# M460 register map
File version: 1.0
Registers are 32-bit, read-write, reset 0x0 unless marked. A register's access mark holds for its fields unless they carry their own. Offsets are from the block's base; [hi:lo] are bit positions; {n}, {i} and the like mark numbered series; 'fields as' and 'values as' point back to an identical list.

## PDMA0 — PDMA Register Map
Base 0x40008000
Same registers: PDMA1 0x40018000
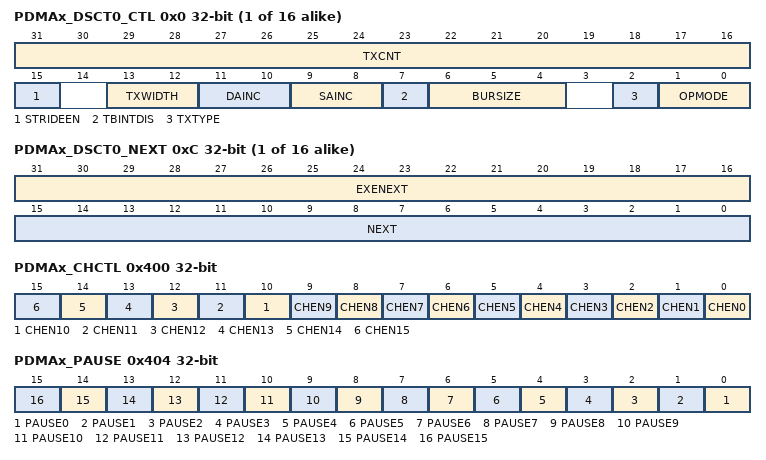
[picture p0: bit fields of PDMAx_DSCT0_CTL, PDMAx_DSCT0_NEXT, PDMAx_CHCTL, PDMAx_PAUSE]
{0x0+0x10*i} PDMAx_DSCT{i}_CTL reset not defined (i=0..15) — Descriptor Table Control Register of PDMA Channel n
  [31:16] TXCNT — Transfer Count. The TXCNT represents the required number of PDMA transfer, the real transfer count is (TXCNT + 1); The maximum transfer count is 65536, every transfer may be byte, half-word or word that is dependent on TXWIDTH field. Note: When PDMA finishes each transfer data, this field will be decreased immediately.
  [15] STRIDEEN — Stride Mode Enable Bit
    0=Stride transfer mode Disabled; 1=Stride transfer mode Enabled
  [13:12] TXWIDTH — Transfer Width Selection. This field is used for transfer width. Note: The PDMA transfer source address (PDMA_DSCTn_SA) and PDMA transfer destination address (PDMA_DSCTn_DA) should be alignment under the TXWIDTH selection
    0=One byte (8 bit) is transferred for every operation; 1=One half-word (16 bit) is transferred for every operation; 2=One word (32-bit) is transferred for every operation
  [11:10] DAINC — Destination Address Increment. This field is used to set the destination address increment size. Note: The fixed address function does not support in memory to memory transfer type.
    3=No increment (fixed address)
  [9:8] SAINC — Source Address Increment. This field is used to set the source address increment size. Note: The fixed address function does not support in memory to memory transfer type.
    3=No increment (fixed address)
  [7] TBINTDIS — Table Interrupt Disable Bit. This field can be used to decide whether to enable table interrupt or not. If the TBINTDIS bit is enabled it will not generates TDIFn(PDMA_TDSTS[7:0]) when PDMA controller finishes transfer task. Note: This function only for Scatter-gather mode.
    0=Table interrupt Enabled; 1=Table interrupt Disabled
  [6:4] BURSIZE — Burst Size. This field is used for peripheral to determine the burst size or used for determine the re-arbitration size. Note: This field is only useful in burst transfer type.
    0=128 Transfers; 1=64 Transfers; 2=32 Transfers; 3=16 Transfers; 4=8 Transfers; 5=4 Transfers; 6=2 Transfers; 7=1 Transfers
  [2] TXTYPE — Transfer Type
    0=Burst transfer type; 1=Single transfer type
  [1:0] OPMODE — PDMA Operation Mode Selection. Note: Before filling new transfer task in the Descriptor Table, user must check the PDMA_INTSTS[1] to make sure the current task is complete.
    0=Idle state: Channel is stopped or this table is complete, when PDMA finish channel table task, OPMODE will be cleared to idle state automatically; 1=Basic mode: The descriptor table only has one task. When this task is finished, the PDMA_INTSTS[1] will be asserted; 2=Scatter-gather mode: When operating in this mode, user must give the next descriptor table address in PDMA_DSCTn_NEXT register; PDMA controller will ignore this task, then load the next task to execute
{0x4+0x10*i} PDMAx_DSCT{i}_SA reset not defined (i=0..15) — Source Address Register of PDMA Channel n
  [31:0] SA — PDMA Transfer Source Address. This field indicates a 32-bit source address of PDMA controller.
{0x8+0x10*i} PDMAx_DSCT{i}_DA reset not defined (i=0..15) — Destination Address Register of PDMA Channel n
  [31:0] DA — PDMA Transfer Destination Address. This field indicates a 32-bit destination address of PDMA controller.
{0xC+0x10*i} PDMAx_DSCT{i}_NEXT reset not defined (i=0..15) — Next Scatter-gather Descriptor Table Offset Address of PDMA Channel n
  [31:16] EXENEXT — PDMA Execution Next Descriptor Table Offset. This field indicates the offset of next descriptor table address of current execution descriptor table in system memory. Note: Write operation is useless in this field.
  [15:0] NEXT — PDMA Next Descriptor Table Offset. This field indicates the offset of the next descriptor table address in system memory. Write Operation: If the system memory based address is 0x2000_0000 (PDMA_SCATBA), and the next descriptor table is start from 0x2000_0100, then this field must fill in 0x0100. Read Operation: When operating in Scatter-gather mode, the last two bits NEXT[1:0] will become reserved, and indicate the first next address of system memory. Note 1: The descriptor table address must be word boundary. Note 2: Before filling transfer task in the descriptor table, user must check if the descriptor table is complete.
{0x80+4i} PDMAx_CURSCAT{i} ro reset not defined (i=0..15) — Current Scatter-gather Descriptor Table Address of PDMA Channel n
  [31:0] CURADDR — PDMA Current Description Address (Read Only). This field indicates a 32-bit current external description address of PDMA controller. Note: This field is read only and used for Scatter-gather mode only to indicate the current external description address.
0x400 PDMAx_CHCTL — PDMA Channel Control Register
  [all] fields
    0=PDMA channel [n] Disabled; 1=PDMA channel [n] Enabled
  [n] CHEN{n} (n=0..15) — PDMA Channel Enable Bits. Set this bit to 1 to enable PDMAn operation. Channel cannot be active if it is not set as enabled. Note: Setting the corresponding bit of PDMA_PAUSE or PDMA_CHRST register will also clear this bit.
0x404 PDMAx_PAUSE wo — PDMA Transfer Pause Control Register
  [all] fields
    0=No effect; 1=Pause PDMA channel n transfer
  [n] PAUSE{n} (n=0..15) — PDMA Channel n Transfer Pause Control (Write Only)
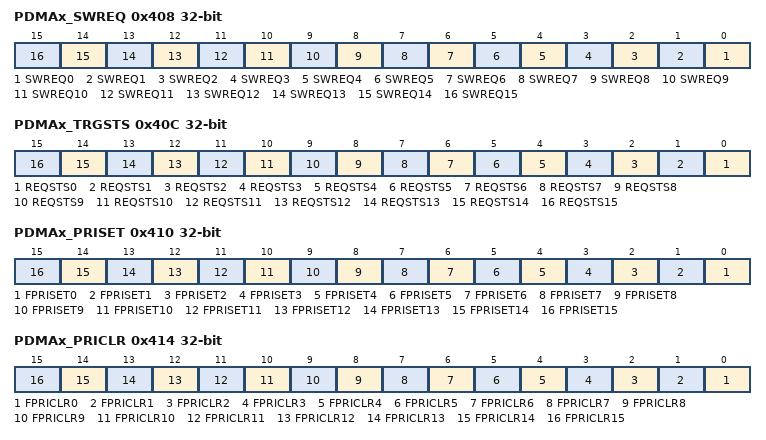
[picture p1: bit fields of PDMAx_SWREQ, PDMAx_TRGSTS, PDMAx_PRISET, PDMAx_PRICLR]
0x408 PDMAx_SWREQ wo — PDMA Software Request Register
  [all] fields
    0=No effect; 1=Generate a software request
  [n] SWREQ{n} (n=0..15) — PDMA Software Request (Write Only). Set this bit to 1 to generate a software request to PDMA [n]. Note 1: User can read PDMA_TRGSTS register to know which channel is on active. Active flag may be triggered by software request or peripheral request. Note 2: If user does not enable corresponding PDMA channel, the software request will be ignored.
0x40C PDMAx_TRGSTS ro — PDMA Channel Request Status Register
  [all] fields
    0=PDMA Channel n has no request; 1=PDMA Channel n has a request
  [n] REQSTS{n} (n=0..15) — PDMA Channel Request Status (Read Only). This flag indicates whether channel[n] have a request or not, no matter request from software or peripheral. When PDMA controller finishes channel transfer, this bit will be cleared automatically. Note: If user pauses or resets each PDMA transfer by setting PDMA_PAUSE or PDMA_CHRST register respectively, this bit will be cleared automatically after finishing the current transfer.
0x410 PDMAx_PRISET — PDMA Fixed Priority Setting Register
  [all] fields
    0=No effect. Corresponding PDMA channel is round-robin priority; 1=Set PDMA channel [n] to fixed priority channel. Corresponding PDMA channel is fixed priority
  [n] FPRISET{n} (n=0..15) — PDMA Fixed Priority Setting. Set this bit to 1 to enable fixed priority level. Write Operation: Note: This field is only set to fixed priority. To clear fixed priority, use PDMA_PRICLR register.
0x414 PDMAx_PRICLR wo — PDMA Fixed Priority Clear Register
  [all] fields
    0=No effect; 1=Clear PDMA channel [n] fixed priority setting
  [n] FPRICLR{n} (n=0..15) — PDMA Fixed Priority Clear Bits (Write Only). Set this bit to 1 to clear fixed priority level. Note: User can read PDMA_PRISET register to know the channel priority.
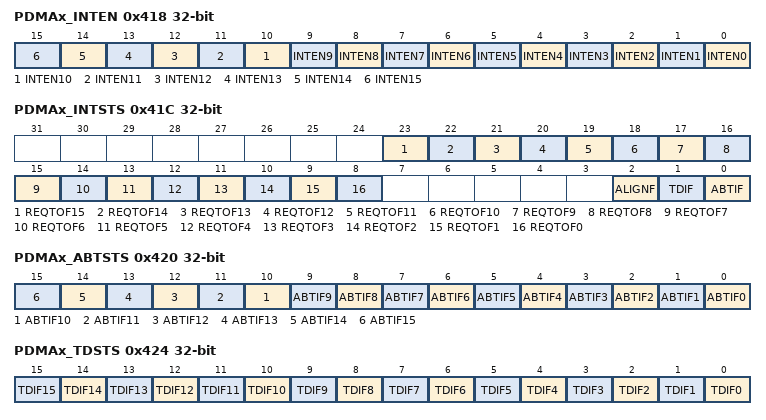
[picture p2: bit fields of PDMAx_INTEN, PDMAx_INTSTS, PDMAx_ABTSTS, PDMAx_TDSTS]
0x418 PDMAx_INTEN — PDMA Interrupt Enable Register
  [all] fields
    0=PDMA channel n interrupt Disabled; 1=PDMA channel n interrupt Enabled
  [n] INTEN{n} (n=0..15) — PDMA Interrupt Enable Bits. This field is used to enable PDMA channel[n] interrupt. Note: The interrupt flag is time-out, abort, transfer done and align.
0x41C PDMAx_INTSTS — PDMA Interrupt Status Register
  [23] REQTOF15 — Request Time-out Flag for Channel 15. This flag indicates that PDMA controller has waited peripheral request for a period defined by TOC15(PDMA_TOC15_14[31:16]). Note 1: Please disable time-out function before clearing this bit. Note 2: This bit will be cleared by writing 1 to it.
    0=No request time-out; 1=Peripheral request time-out
  [22] REQTOF14 — Request Time-out Flag for Channel 14. This flag indicates that PDMA controller has waited peripheral request for a period defined by TOC14(PDMA_TOC15_14[15:0]). Note 1: Please disable time-out function before clearing this bit. Note 2: This bit will be cleared by writing 1 to it.
    0=No request time-out; 1=Peripheral request time-out
  [21] REQTOF13 — Request Time-out Flag for Channel 13. This flag indicates that PDMA controller has waited peripheral request for a period defined by TOC13(PDMA_TOC13_12[31:16]). Note 1: Please disable time-out function before clearing this bit. Note 2: This bit will be cleared by writing 1 to it.
    0=No request time-out; 1=Peripheral request time-out
  [20] REQTOF12 — Request Time-out Flag for Channel 12. This flag indicates that PDMA controller has waited peripheral request for a period defined by TOC12(PDMA_TOC13_12[15:0]). Note 1: Please disable time-out function before clearing this bit. Note 2: This bit will be cleared by writing 1 to it.
    0=No request time-out; 1=Peripheral request time-out
  [19] REQTOF11 — Request Time-out Flag for Channel 11. This flag indicates that PDMA controller has waited peripheral request for a period defined by TOC11(PDMA_TOC10_11[31:16]). Note 1: Please disable time-out function before clearing this bit. Note 2: This bit will be cleared by writing 1 to it.
    0=No request time-out; 1=Peripheral request time-out
  [18] REQTOF10 — Request Time-out Flag for Channel 10. This flag indicates that PDMA controller has waited peripheral request for a period defined by TOC10(PDMA_TOC10_11[15:0]). Note 1: Please disable time-out function before clearing this bit. Note 2: This bit will be cleared by writing 1 to it.
    0=No request time-out; 1=Peripheral request time-out
  [17] REQTOF9 — Request Time-out Flag for Channel 9. This flag indicates that PDMA controller has waited peripheral request for a period defined by TOC9(PDMA_TOC8_9[31:16]). Note 1: Please disable time-out function before clearing this bit. Note 2: This bit will be cleared by writing 1 to it.
    0=No request time-out; 1=Peripheral request time-out
  [16] REQTOF8 — Request Time-out Flag for Channel 8. This flag indicates that PDMA controller has waited peripheral request for a period defined by TOC8(PDMA_TOC8_9[15:0]). Note 1: Please disable time-out function before clearing this bit. Note 2: This bit will be cleared by writing 1 to it.
    0=No request time-out; 1=Peripheral request time-out
  [15] REQTOF7 — Request Time-out Flag for Channel 7. This flag indicates that PDMA controller has waited peripheral request for a period defined by TOC7(PDMA_TOC6_7[31:16]). Note 1: Please disable time-out function before clearing this bit. Note 2: This bit will be cleared by writing 1 to it.
    0=No request time-out; 1=Peripheral request time-out
  [14] REQTOF6 — Request Time-out Flag for Channel 6. This flag indicates that PDMA controller has waited peripheral request for a period defined by TOC6(PDMA_TOC6_7[15:0]). Note 1: Please disable time-out function before clearing this bit. Note 2: This bit will be cleared by writing 1 to it.
    0=No request time-out; 1=Peripheral request time-out
  [13] REQTOF5 — Request Time-out Flag for Channel 5. This flag indicates that PDMA controller has waited peripheral request for a period defined by TOC5(PDMA_TOC4_5[31:16]). Note 1: Please disable time-out function before clearing this bit. Note 2: This bit will be cleared by writing 1 to it.
    0=No request time-out; 1=Peripheral request time-out
  [12] REQTOF4 — Request Time-out Flag for Channel 4. This flag indicates that PDMA controller has waited peripheral request for a period defined by TOC4(PDMA_TOC4_5[15:0]). Note 1: Please disable time-out function before clearing this bit. Note 2: This bit will be cleared by writing 1 to it.
    0=No request time-out; 1=Peripheral request time-out
  [11] REQTOF3 — Request Time-out Flag for Channel 3. This flag indicates that PDMA controller has waited peripheral request for a period defined by TOC3(PDMA_TOC2_3[31:16]). Note 1: Please disable time-out function before clearing this bit. Note 2: This bit will be cleared by writing 1 to it.
    0=No request time-out; 1=Peripheral request time-out
  [10] REQTOF2 — Request Time-out Flag for Channel 2. This flag indicates that PDMA controller has waited peripheral request for a period defined by TOC2(PDMA_TOC2_3[15:0]). Note 1: Please disable time-out function before clearing this bit. Note 2: This bit will be cleared by writing 1 to it.
    0=No request time-out; 1=Peripheral request time-out
  [9] REQTOF1 — Request Time-out Flag for Channel 1. This flag indicates that PDMA controller has waited peripheral request for a period defined by TOC1(PDMA_TOC0_1[31:16]). Note 1: Please disable time-out function before clearing this bit. Note 2: This bit will be cleared by writing 1 to it.
    0=No request time-out; 1=Peripheral request time-out
  [8] REQTOF0 — Request Time-out Flag for Channel 0. This flag indicates that PDMA controller has waited peripheral request for a period defined by TOC0(PDMA_TOC0_1[15:0]. Note 1: Please disable time-out function before clearing this bit. Note 2: This bit will be cleared by writing 1 to it.
    0=No request time-out; 1=Peripheral request time-out
  [2] ALIGNF ro — Transfer Alignment Interrupt Flag (Read Only)
    0=PDMA channel source address and destination address both follow transfer width setting; 1=PDMA channel source address or destination address is not follow transfer width setting
  [1] TDIF ro — Transfer Done Interrupt Flag (Read Only). This bit indicates that PDMA controller has finished transmission; User can read PDMA_TDSTS register to indicate which channel finished transfer.
    0=Not finished yet; 1=PDMA channel has finished transmission
  [0] ABTIF ro — PDMA Read/Write Target Abort Interrupt Flag (Read Only). This bit indicates that PDMA has target abort error; Software can read PDMA_ABTSTS register to find which channel has target abort error.
    0=No AHB bus ERROR response received; 1=AHB bus ERROR response received
0x420 PDMAx_ABTSTS — PDMA Channel Read/Write Target Abort Flag Register
  [all] fields
    0=No AHB bus ERROR response received when channel n transfer; 1=AHB bus ERROR response received when channel n transfer
  [n] ABTIF{n} (n=0..15) — PDMA Read/Write Target Abort Interrupt Status Flag. This bit indicates which PDMA controller has target abort error. Note 1: If channel n target abort, REQSRCn should set0 to disable peripheral request. Note 2 This bit will be cleared by writing 1 to it.
0x424 PDMAx_TDSTS — PDMA Channel Transfer Done Flag Register
  [all] fields
    0=PDMA channel transfer has not finished; 1=PDMA channel has finished transmission
  [n] TDIF{n} (n=0..15) — Transfer Done Flag. This bit indicates whether PDMA controller channel transfer has been finished or not. Note: User can write 1 to clear these bits.
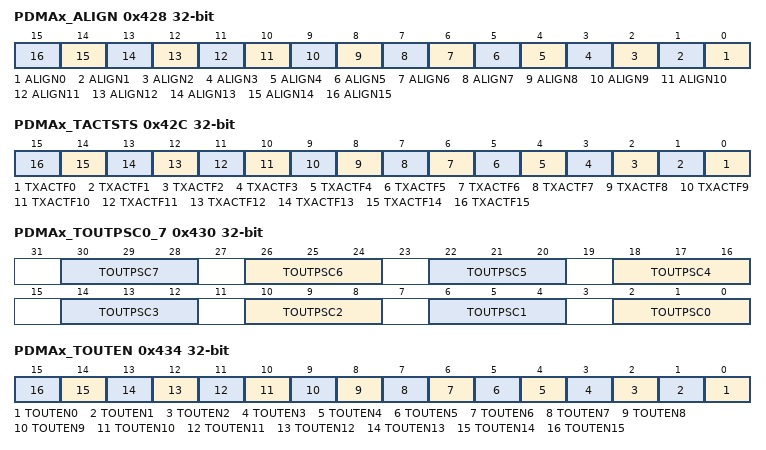
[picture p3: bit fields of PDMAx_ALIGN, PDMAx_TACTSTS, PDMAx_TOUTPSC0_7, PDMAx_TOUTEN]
0x428 PDMAx_ALIGN — PDMA Transfer Alignment Status Register
  [all] fields
    values as PDMAx_INTSTS.ALIGNF
  [n] ALIGN{n} (n=0..15) — Transfer Alignment Flag. This bit indicates whether source and destination address both follow transfer width setting. Note: User can write 1 to clear these bits.
0x42C PDMAx_TACTSTS ro — PDMA Transfer Active Flag Register
  [all] fields
    0=PDMA channel is finished; 1=PDMA channel is active
  [n] TXACTF{n} (n=0..15) — Transfer on Active Flag (Read Only). This bit indicates which PDMA channel is in active.
0x430 PDMAx_TOUTPSC0_7 — PDMA Time-out Prescaler Register(CH0 to CH7)
  [4n+2:4n] TOUTPSC{n} (n=0..7) — PDMA Channel {n} Time-out Clock Source Prescaler Bits
    0=PDMA channel {n} time-out clock source is HCLK/28; 1=PDMA channel {n} time-out clock source is HCLK/29; {v}=PDMA channel {n} time-out clock source is HCLK/{v+208} (v=2..7)
0x434 PDMAx_TOUTEN — PDMA Time-out Enable Register
  [all] fields
    0=PDMA Channel n time-out function Disabled; 1=PDMA Channel n time-out function Enabled
  [n] TOUTEN{n} (n=0..15) — PDMA Time-out Enable Bits
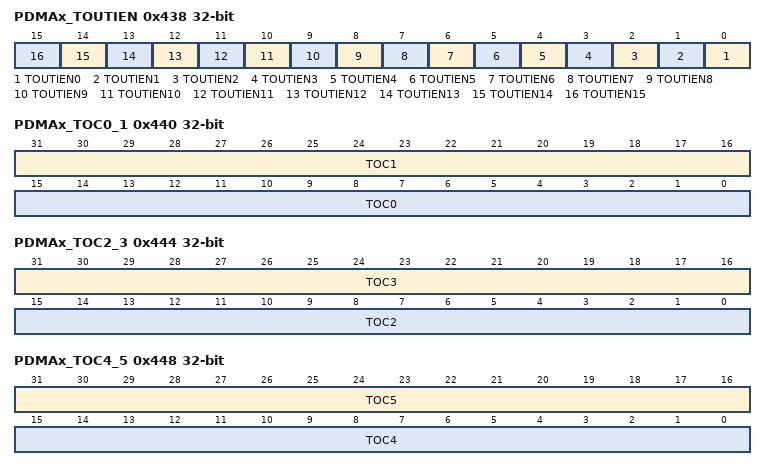
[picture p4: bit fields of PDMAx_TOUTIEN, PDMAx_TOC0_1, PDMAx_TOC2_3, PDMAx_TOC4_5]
0x438 PDMAx_TOUTIEN — PDMA Time-out Interrupt Enable Register
  [all] fields
    0=PDMA Channel n time-out interrupt Disabled; 1=PDMA Channel n time-out interrupt Enabled
  [n] TOUTIEN{n} (n=0..15) — PDMA Time-out Interrupt Enable Bits
0x43C PDMAx_SCATBA reset 0x20000000 — PDMA Scatter-gather Descriptor Table Base Address Register
  [31:16] SCATBA — PDMA Scatter-gather Descriptor Table Address. In Scatter-gather mode, this is the base address for calculating the next link - list address. The next link address equation is. Note: Only useful in Scatter-gather mode.
0x440 PDMAx_TOC0_1 — PDMA Time-out Counter Ch0 and Ch1 Register
  [31:16] TOC1 — Time-out Counter for Channel 1. This controls the period of time-out function for channel 1. The calculation unit is based on TOUTPSC1 (PDMA_TOUTPSC0_7[6:4]) clock. The example of time-out period can refer TOC0 bit description.
  [15:0] TOC0 — Time-out Counter for Channel 0. This controls the period of time-out function for channel 0. The calculation unit is based on TOUTPSC0 (PDMA_TOUTPSC0_7[2:0]) clock.
0x444 PDMAx_TOC2_3 — PDMA Time-out Counter Ch2 and Ch3 Register
  [31:16] TOC3 — Time-out Counter for Channel 3. This controls the period of time-out function for channel 3. The calculation unit is based on TOUTPSC3 (PDMA_TOUTPSC0_7[14:12]) clock. The example of time-out period can refer TOC0 bit description.
  [15:0] TOC2 — Time-out Counter for Channel 2. This controls the period of time-out function for channel 2. The calculation unit is based on TOUTPSC2 (PDMA_TOUTPSC0_7[10:8]) clock.
0x448 PDMAx_TOC4_5 — PDMA Time-out Counter Ch4 and Ch5 Register
  [31:16] TOC5 — Time-out Counter for Channel 5. This controls the period of time-out function for channel 5. The calculation unit is based on TOUTPSC5 (PDMA_TOUTPSC0_7[22:20]) clock. The example of time-out period can refer TOC0 bit description.
  [15:0] TOC4 — Time-out Counter for Channel 4. This controls the period of time-out function for channel 4. The calculation unit is based on TOUTPSC4 (PDMA_TOUTPSC0_7[18:16]) clock.
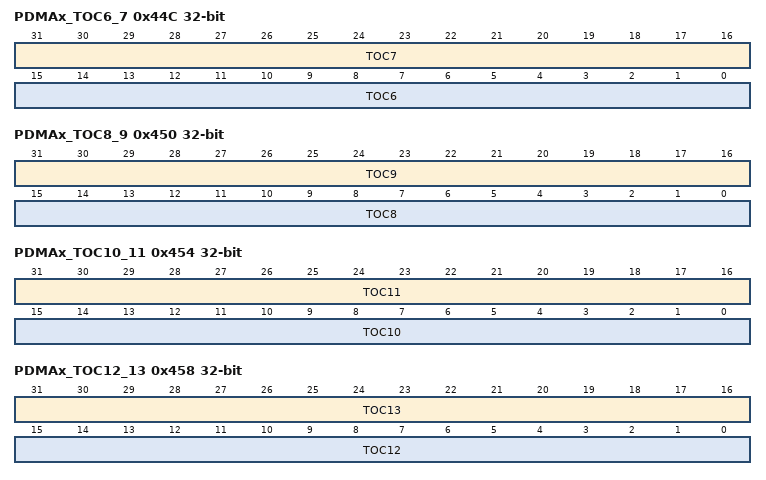
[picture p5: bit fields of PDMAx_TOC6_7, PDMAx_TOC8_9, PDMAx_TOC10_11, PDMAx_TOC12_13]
0x44C PDMAx_TOC6_7 — PDMA Time-out Counter Ch6 and Ch7 Register
  [31:16] TOC7 — Time-out Counter for Channel 7. This controls the period of time-out function for channel 7. The calculation unit is based on TOUTPSC7 (PDMA_TOUTPSC0_7[30:28]) clock. The example of time-out period can refer TOC0 bit description.
  [15:0] TOC6 — Time-out Counter for Channel 6. This controls the period of time-out function for channel 6. The calculation unit is based on TOUTPSC6 (PDMA_TOUTPSC0_7[26:24]) clock.
0x450 PDMAx_TOC8_9 — PDMA Time-out Counter Ch8 and Ch9 Register
  [31:16] TOC9 — Time-out Counter for Channel 9. This controls the period of time-out function for channel 9. The calculation unit is based on TOUTPSC9 (PDMA_TOUTPSC8_15[6:4]) clock. The example of time-out period can refer TOC0 bit description.
  [15:0] TOC8 — Time-out Counter for Channel 8. This controls the period of time-out function for channel 8. The calculation unit is based on TOUTPSC8 (PDMA_TOUTPSC8_15[2:0]) clock.
0x454 PDMAx_TOC10_11 — PDMA Time-out Counter Ch10 and Ch11 Register
  [31:16] TOC11 — Time-out Counter for Channel 11. This controls the period of time-out function for channel 11. The calculation unit is based on TOUTPSC11 (PDMA_TOUTPSC8_15[14:12]) clock. The example of time-out period can refer TOC0 bit description.
  [15:0] TOC10 — Time-out Counter for Channel 10. This controls the period of time-out function for channel 10. The calculation unit is based on TOUTPSC10 (PDMA_TOUTPSC8_15[10:8]) clock.
0x458 PDMAx_TOC12_13 — PDMA Time-out Counter Ch12 and Ch13 Register
  [31:16] TOC13 — Time-out Counter for Channel 13. This controls the period of time-out function for channel 13. The calculation unit is based on TOUTPSC13 (PDMA_TOUTPSC8_15[22:20]) clock. The example of time-out period can refer TOC0 bit description.
  [15:0] TOC12 — Time-out Counter for Channel 12. This controls the period of time-out function for channel 12. The calculation unit is based on TOUTPSC12 (PDMA_TOUTPSC8_15[18:16]) clock.
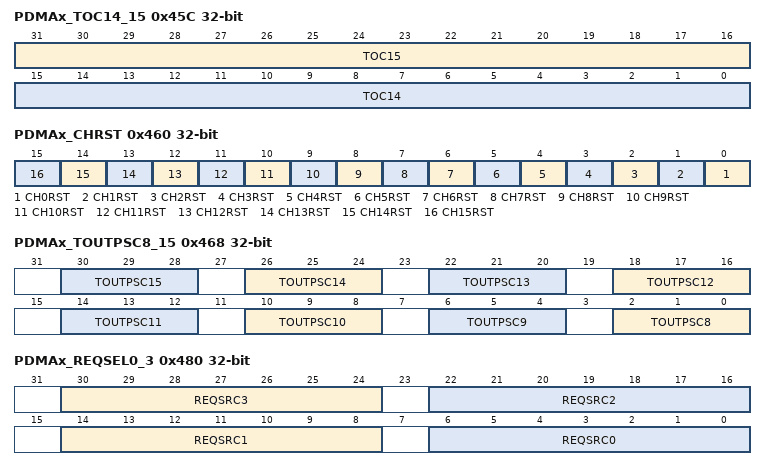
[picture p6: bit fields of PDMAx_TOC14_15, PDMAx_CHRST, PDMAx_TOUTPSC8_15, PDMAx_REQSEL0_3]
0x45C PDMAx_TOC14_15 — PDMA Time-out Counter Ch14 and Ch15 Register
  [31:16] TOC15 — Time-out Counter for Channel 15. This controls the period of time-out function for channel 15. The calculation unit is based on TOUTPSC15 (PDMA_TOUTPSC8_15[30:28]) clock. The example of time-out period can refer TOC0 bit description.
  [15:0] TOC14 — Time-out Counter for Channel 14. This controls the period of time-out function for channel 14. The calculation unit is based on TOUTPSC14 (PDMA_TOUTPSC8_15[26:24]) clock.
0x460 PDMAx_CHRST — PDMA Channel Reset Register
  [all] fields
    0=Corresponding channel n is not reset; 1=Corresponding channel n is reset
  [n] CH{n}RST (n=0..15) — Channel n Reset
0x468 PDMAx_TOUTPSC8_15 — PDMA Time-out Prescaler Register(CH8 to CH15)
  [4n-30:4n-32] TOUTPSC{n} (n=8..15) — PDMA Channel {n} Time-out Clock Source Prescaler Bits
    values as PDMAx_TOUTPSC0_7.TOUTPSC0
0x480 PDMAx_REQSEL0_3 — PDMA Request Source Select Register 0
  [30:24] REQSRC3 — Channel 3 Request Source Selection. This filed defines which peripheral is connected to PDMA channel 3. User can configure the peripheral setting by REQSRC3. Note: The channel configuration is the same as REQSRC0 field. Please refer to the explanation of REQSRC0.
  [22:16] REQSRC2 — Channel 2 Request Source Selection. This filed defines which peripheral is connected to PDMA channel 2. User can configure the peripheral setting by REQSRC2. Note: The channel configuration is the same as REQSRC0 field. Please refer to the explanation of REQSRC0.
  [14:8] REQSRC1 — Channel 1 Request Source Selection. This filed defines which peripheral is connected to PDMA channel 1. User can configure the peripheral setting by REQSRC1. Note: The channel configuration is the same as REQSRC0 field. Please refer to the explanation of REQSRC0.
  [6:0] REQSRC0 — Channel 0 Request Source Selection. This filed defines which peripheral is connected to PDMA channel 0. User can configure the peripheral by setting REQSRC0. Note 1: A peripheral cannot be assigned to two channels at the same time. Note 2: This field is useless when transfer between memory and memory.
    0=Disable PDMA peripheral request; 2=Channel connects to USB_TX; 3=Channel connects to USB_RX; 4=Channel connects to UART0_TX; 5=Channel connects to UART0_RX; 6=Channel connects to UART1_TX; 7=Channel connects to UART1_RX; 8=Channel connects to UART2_TX; 9=Channel connects to UART2_RX; 10=Channel connects to UART3_TX; 11=Channel connects to UART3_RX; 12=Channel connects to UART4_TX; 13=Channel connects to UART4_RX; 14=Channel connects to UART5_TX; 15=Channel connects to UART5_RX; 16=Channel connects to USCI0_TX; 17=Channel connects to USCI0_RX; 20=Channel connects to QSPI0_TX; 21=Channel connects to QSPI0_RX; 22=Channel connects to SPI0_TX; 23=Channel connects to SPI0_RX; 24=Channel connects to SPI1_TX; 25=Channel connects to SPI1_RX; 26=Channel connects to SPI2_TX; 27=Channel connects to SPI2_RX; 28=Channel connects to SPI3_TX; 29=Channel connects to SPI3_RX; 30=Channel connects to QSPI1_TX; 31=Channel connects to QSPI1_RX; 32=Channel connects to EPWM0_P1_RX; 33=Channel connects to EPWM0_P2_RX; 34=Channel connects to EPWM0_P3_RX; 35=Channel connects to EPWM1_P1_RX; 36=Channel connects to EPWM1_P2_RX; 37=Channel connects to EPWM1_P3_RX; 38=Channel connects to I2C0_TX; 39=Channel connects to I2C0_RX; 40=Channel connects to I2C1_TX; 41=Channel connects to I2C1_RX; 42=Channel connects to I2C2_TX; 43=Channel connects to I2C2_RX; 44=Channel connects to I2S0_TX; 45=Channel connects to I2S0_RX; {v}=Channel connects to TMR{v-46} (v=46..49); 50=Channel connects to ADC0_RX; 51=Channel connects to DAC0_TX; 52=Channel connects to DAC1_TX; {v}=Channel connects to EPWM0_CH{v-53}_TX (v=53..58); {v}=Channel connects to EPWM1_CH{v-59}_TX (v=59..64); 66=Channel connects to UART6_TX; 67=Channel connects to UART6_RX; 68=Channel connects to UART7_TX; 69=Channel connects to UART7_RX; 70=Channel connects to ADC1_RX; 71=Channel connects to ACMP0; 72=Channel connects to ACMP1; 73=Channel connects to PSIO_TX; 74=Channel connects to PSIO_RX; 75=Channel connects to I2C3_TX; 76=Channel connects to I2C3_RX; 77=Channel connects to I2C4_TX; 78=Channel connects to I2C4_RX; 79=Channel connects to I2S1_TX; 80=Channel connects to I2S1_RX; {v}=Channel connects to EINT{v-81} (v=81..88); 89=Channel connects to UART8_TX; 90=Channel connects to UART8_RX; 91=Channel connects to UART9_TX; 92=Channel connects to UART9_RX; 93=Channel connects to ADC2_RX; 94=Channel connects to ACMP2; 95=Channel connects to ACMP3; 96=Channel connects to SPI4_TX; 97=Channel connects to SPI4_RX; 98=Channel connects to SPI5_TX; 99=Channel connects to SPI5_RX; 100=Channel connects to SPI6_TX; 101=Channel connects to SPI6_RX; 102=Channel connects to SPI7_TX; 103=Channel connects to SPI7_RX; 104=Channel connects to SPI8_TX; 105=Channel connects to SPI8_RX; 106=Channel connects to SPI9_TX; 107=Channel connects to SPI9_RX; 108=Channel connects to SPI10_TX; 109=Channel connects to SPI10_RX
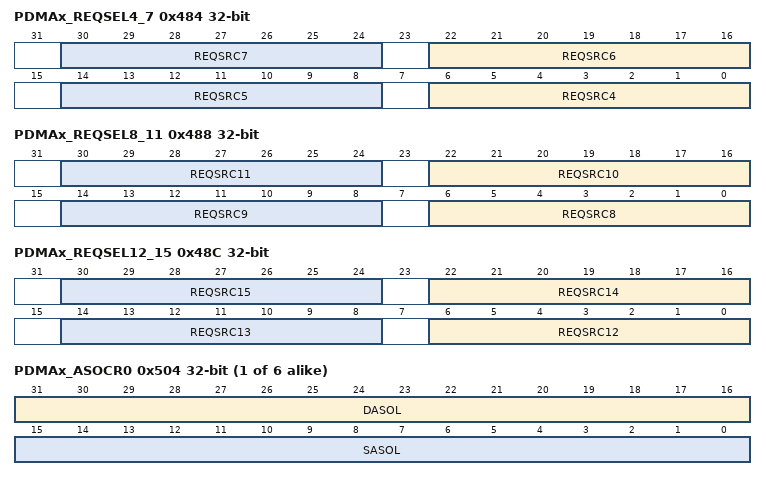
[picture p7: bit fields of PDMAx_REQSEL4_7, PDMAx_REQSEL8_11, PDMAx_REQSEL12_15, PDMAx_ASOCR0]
0x484 PDMAx_REQSEL4_7 — PDMA Request Source Select Register 1
  [8n-26:8n-32] REQSRC{n} (n=4..7) — Channel {n} Request Source Selection. This filed defines which peripheral is connected to PDMA channel {n}. User can configure the peripheral setting by REQSRC{n}. Note: The channel configuration is the same as REQSRC0 field. Please refer to the explanation of REQSRC0.
0x488 PDMAx_REQSEL8_11 — PDMA Request Source Select Register 2
  [8n-58:8n-64] REQSRC{n} (n=8..11) — Channel {n} Request Source Selection. This filed defines which peripheral is connected to PDMA channel {n}. User can configure the peripheral setting by REQSRC{n}. Note: The channel configuration is the same as REQSRC0 field. Please refer to the explanation of REQSRC0.
0x48C PDMAx_REQSEL12_15 — PDMA Request Source Select Register 3
  [8n-90:8n-96] REQSRC{n} (n=12..15) — Channel {n} Request Source Selection. This filed defines which peripheral is connected to PDMA channel {n}. User can configure the peripheral setting by REQSRC{n}. Note: The channel configuration is the same as REQSRC0 field. Please refer to the explanation of REQSRC0.
{0x500+8i} PDMAx_STCR{i} (i=0..5) — Stride Transfer Count Register of PDMA Channel {i}
  [15:0] STC — PDMA Stride Transfer Count. The 16-bit register defines the stride transfer count of each row.
{0x504+8i} PDMAx_ASOCR{i} (i=0..5) — Address Stride Offset Register of PDMA Channel {i}
  [31:16] DASOL — PDMA Destination Address Stride Offset Length. The 16-bit register defines the destination address stride transfer offset count of each row.
  [15:0] SASOL — PDMA Source Address Stride Offset Length. The 16-bit register defines the source address stride transfer offset count of each row.
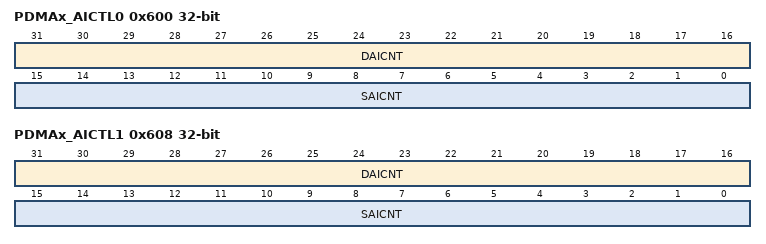
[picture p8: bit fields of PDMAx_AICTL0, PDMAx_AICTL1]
0x600 PDMAx_AICTL0 — Address Interval Control Register of PDMA Channel 0
  [31:16] DAICNT — PDMA Destination Address Interval Count. The 16-bit register defines the destination address interval count of each row.
  [15:0] SAICNT — PDMA Source Address Interval Count. The 16-bit register defines the source address interval count of each row.
0x604 PDMAx_RCNT0 — Repeat Count Register of PDMA Channel 0
  [15:0] RCNT — PDMA Repeat Count. The 16-bit register defines the repeat times of block transfer.
0x608 PDMAx_AICTL1 — Address Interval Control Register of PDMA Channel 1
  fields as PDMAx_AICTL0
0x60C PDMAx_RCNT1 — Repeat Count Register of PDMA Channel 1
  fields as PDMAx_RCNT0
